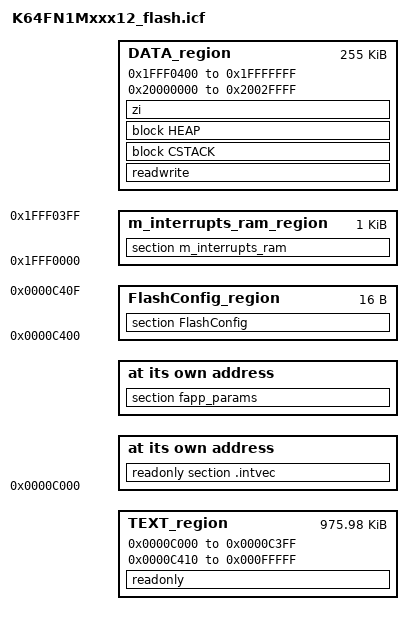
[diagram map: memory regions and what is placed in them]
/* Linker file for IAR ARM C Compiler */
define symbol m_interrupts_start       = 0x0000C000; //48KB reserved for FNET bootloader.
define symbol m_interrupts_end         = 0x0000C3FF;      

define symbol m_text_start             = 0x0000C410;
define symbol m_text_end               = 0x000FFFFF;      

define symbol m_interrupts_ram_start   = 0x1FFF0000;
define symbol m_interrupts_ram_end     = 0x1FFF03FF;      

define symbol m_data_1FFF0400_start    = 0x1FFF0400;
define symbol m_data_1FFF0400_end      = 0x1FFFFFFF;      

define symbol m_data_start             = 0x20000000;
define symbol m_data_end               = 0x2002FFFF;      

define symbol FlashConfig_start__      = 0x0000C400;
define symbol FlashConfig_end__        = 0x0000C40f;

define symbol FappParams_start__= m_text_end + 1 - (4*0x400);               //FAPP
define symbol FappParams_end__  = m_text_end;                               //FAPP

/*-Sizes-*/
define symbol __size_cstack__          = 0x2000;
define symbol __size_heap__            = 0x2000;
define exported symbol __VECTOR_TABLE  = m_interrupts_start;
define exported symbol __VECTOR_RAM    = m_interrupts_ram_start;
  
define memory mem with size = 4G;
define region FlashConfig_region = mem:[from FlashConfig_start__ to FlashConfig_end__];
define region TEXT_region = mem:[from m_interrupts_start to m_interrupts_end]
                          | mem:[from m_text_start to m_text_end];
define region DATA_region = mem:[from m_data_1FFF0400_start to m_data_1FFF0400_end]
                          | mem:[from m_data_start to m_data_end];
define region m_interrupts_ram_region = mem:[from m_interrupts_ram_start to m_interrupts_ram_end];

define region FappParams_region = mem:[from FappParams_start__ to FappParams_end__];    //FAPP
  
define block CSTACK    with alignment = 8, size = __size_cstack__   { };
define block HEAP      with alignment = 8, size = __size_heap__     { };

initialize by copy { readwrite, section .textrw };
do not initialize  { section .noinit };
  
place at address mem: m_interrupts_start    { readonly section .intvec };
place at address mem: FappParams_start__ { section fapp_params };           //FAPP

place in FlashConfig_region                 { section FlashConfig };
place in TEXT_region                        { readonly };
place in DATA_region                        { readwrite, block CSTACK, block HEAP };
place in DATA_region                        { zi };
place in m_interrupts_ram_region            { section m_interrupts_ram };

//place in FappParams_region                  { section .fapp_params };       //FAPP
